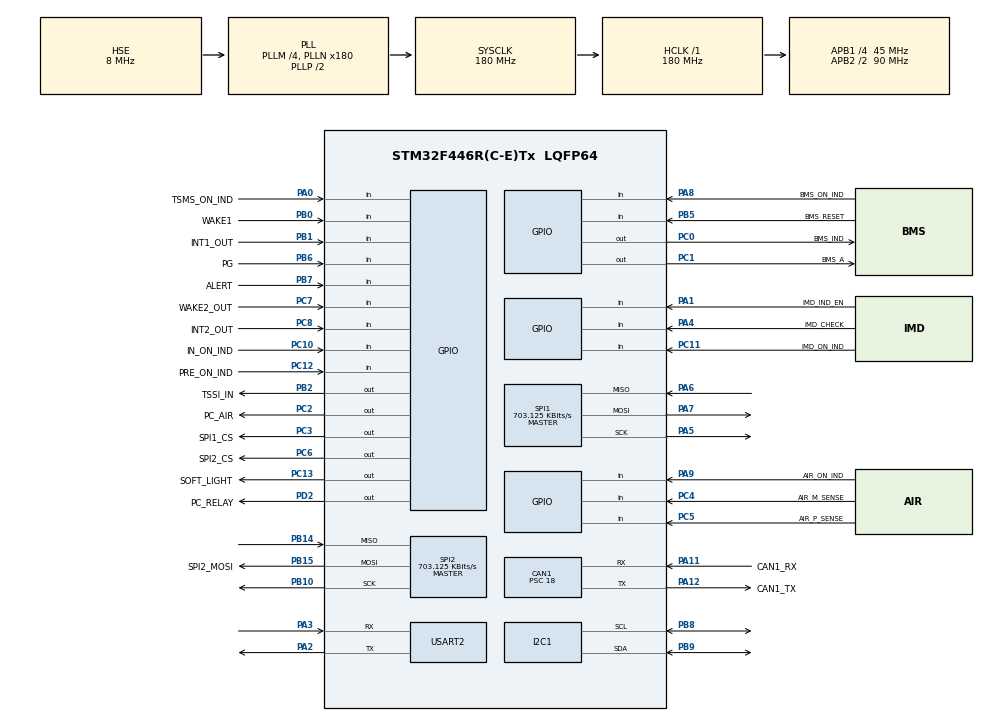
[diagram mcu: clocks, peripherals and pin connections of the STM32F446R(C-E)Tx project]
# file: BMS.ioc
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CAN1.BS1=CAN_BS1_3TQ
CAN1.CalculateBaudRate=500000
CAN1.CalculateTimeBit=2000
CAN1.CalculateTimeQuantum=400.0
CAN1.Prescaler=18
Dma.Request0=USART2_RX
Dma.Request1=USART2_TX
Dma.USART2_RX.0.Direction=DMA_PERIPH_TO_MEMORY
Dma.USART2_RX.0.FIFOMode=DMA_FIFOMODE_DISABLE
Dma.USART2_RX.0.Instance=DMA1_Stream5
Dma.USART2_RX.0.MemDataAlignment=DMA_MDATAALIGN_BYTE
Dma.USART2_RX.0.MemInc=DMA_MINC_ENABLE
Dma.USART2_RX.0.Mode=DMA_CIRCULAR
Dma.USART2_RX.0.PeriphDataAlignment=DMA_PDATAALIGN_BYTE
Dma.USART2_RX.0.PeriphInc=DMA_PINC_DISABLE
Dma.USART2_RX.0.Priority=DMA_PRIORITY_LOW
Dma.USART2_TX.1.Direction=DMA_MEMORY_TO_PERIPH
Dma.USART2_TX.1.FIFOMode=DMA_FIFOMODE_DISABLE
Dma.USART2_TX.1.Instance=DMA1_Stream6
Dma.USART2_TX.1.MemDataAlignment=DMA_MDATAALIGN_BYTE
Dma.USART2_TX.1.MemInc=DMA_MINC_ENABLE
Dma.USART2_TX.1.Mode=DMA_NORMAL
Dma.USART2_TX.1.PeriphDataAlignment=DMA_PDATAALIGN_BYTE
Dma.USART2_TX.1.PeriphInc=DMA_PINC_DISABLE
Dma.USART2_TX.1.Priority=DMA_PRIORITY_LOW
FREERTOS.CountingSemaphores01=canTxMailboxSem,3,Dynamic,NULL,3;uartTxSem,1,Dynamic,NULL,0
FREERTOS.Mutexes01=ADBMSMutex,Dynamic,NULL,Available;canTxMutex,Dynamic,NULL,Available;canRxMutex,Dynamic,NULL,Available;tpsDataMutex,Dynamic,NULL,Available;tpsI2cMutex,Dynamic,NULL,Available;logMutex,Dynamic,NULL,Available;uartTxMutex,Dynamic,NULL,Available
FREERTOS.Queues01=canTxQueue,16,FEB_CAN_Message_t,0,Dynamic,NULL,NULL;canRxQueue,32,FEB_CAN_Message_t,0,Dynamic,NULL,NULL;uartRxQueue,8,FEB_UART_RxQueueMsg_t,0,Dynamic,NULL,NULL
FREERTOS.Tasks01=uartRxTask,24,1024,StartUartRxTask,As weak,NULL,Dynamic,NULL,NULL;ADBMSTask,48,2048,StartADBMSTask,As weak,NULL,Dynamic,NULL,NULL;TPSTask,8,512,StartTPSTask,As weak,NULL,Dynamic,NULL,NULL;BMSTaskRx,8,1024,StartBMSTaskRx,As weak,NULL,Dynamic,NULL,NULL;BMSTaskTx,8,1024,StartBMSTaskTx,As weak,NULL,Dynamic,NULL,NULL;SMTask,24,1024,StartSMTask,As weak,NULL,Dynamic,NULL,NULL
FREERTOS.configCHECK_FOR_STACK_OVERFLOW=2
FREERTOS.configENABLE_FPU=1
FREERTOS.configTOTAL_HEAP_SIZE=65536
Mcu.Family=STM32F4
Mcu.Name=STM32F446R(C-E)Tx
Mcu.Package=LQFP64
NVIC.CAN1_RX0_IRQn=true\:5\:0\:false\:false\:true\:true\:true\:true\:true
NVIC.CAN1_RX1_IRQn=true\:5\:0\:false\:false\:true\:true\:true\:true\:true
NVIC.CAN1_SCE_IRQn=true\:5\:0\:false\:false\:true\:true\:true\:true\:true
NVIC.CAN1_TX_IRQn=true\:5\:0\:false\:false\:true\:true\:true\:true\:true
NVIC.DMA1_Stream5_IRQn=true\:5\:0\:false\:false\:true\:true\:false\:true\:true
NVIC.DMA1_Stream6_IRQn=true\:5\:0\:false\:false\:true\:true\:false\:true\:true
NVIC.PriorityGroup=NVIC_PRIORITYGROUP_4
NVIC.TIM6_DAC_IRQn=true\:15\:0\:false\:false\:true\:false\:false\:true\:true
NVIC.TimeBase=TIM6_DAC_IRQn
NVIC.TimeBaseIP=TIM6
NVIC.USART2_IRQn=true\:5\:0\:false\:false\:true\:true\:true\:true\:true
PA0-WKUP.GPIO_Label=TSMS_ON_IND
PA0-WKUP.Signal=GPIO_Input
PA1.GPIO_Label=IMD_IND_EN
PA1.Signal=GPIO_Input
PA11.GPIO_Label=CAN1_RX
PA11.Mode=CAN_Activate
PA11.Signal=CAN1_RX
PA12.GPIO_Label=CAN1_TX
PA12.Mode=CAN_Activate
PA12.Signal=CAN1_TX
PA13.Mode=Serial_Wire
PA13.Signal=SYS_JTMS-SWDIO
PA14.Mode=Serial_Wire
PA14.Signal=SYS_JTCK-SWCLK
PA2.Mode=Asynchronous
PA2.Signal=USART2_TX
PA3.Mode=Asynchronous
PA3.Signal=USART2_RX
PA4.GPIO_Label=IMD_CHECK
PA4.Signal=GPIO_Input
PA5.Mode=Full_Duplex_Master
PA5.Signal=SPI1_SCK
PA6.Mode=Full_Duplex_Master
PA6.Signal=SPI1_MISO
PA7.Mode=Full_Duplex_Master
PA7.Signal=SPI1_MOSI
PA8.GPIO_Label=BMS_ON_IND
PA8.Signal=GPIO_Input
PA9.GPIO_Label=AIR_ON_IND
PA9.Signal=GPIO_Input
PB0.GPIO_Label=WAKE1
PB0.Signal=GPIO_Input
PB1.GPIO_Label=INT1_OUT
PB1.Signal=GPIO_Input
PB10.Mode=Full_Duplex_Master
PB10.Signal=SPI2_SCK
PB14.Mode=Full_Duplex_Master
PB14.Signal=SPI2_MISO
PB15.GPIO_Label=SPI2_MOSI
PB15.Mode=Full_Duplex_Master
PB15.Signal=SPI2_MOSI
PB2.GPIO_Label=TSSI_IN
PB2.Signal=GPIO_Output
PB5.GPIO_Label=BMS_RESET
PB5.GPIO_PuPd=GPIO_PULLUP
PB5.Signal=GPIO_Input
PB6.GPIO_Label=PG
PB6.Signal=GPIO_Input
PB7.GPIO_Label=ALERT
PB7.Signal=GPIO_Input
PB8.Mode=I2C
PB8.Signal=I2C1_SCL
PB9.Mode=I2C
PB9.Signal=I2C1_SDA
PC0.GPIO_Label=BMS_IND
PC0.Signal=GPIO_Output
PC1.GPIO_Label=BMS_A
PC1.Signal=GPIO_Output
PC10.GPIO_Label=IN_ON_IND
PC10.Signal=GPIO_Input
PC11.GPIO_Label=IMD_ON_IND
PC11.Signal=GPIO_Input
PC12.GPIO_Label=PRE_ON_IND
PC12.Signal=GPIO_Input
PC13.GPIO_Label=SOFT_LIGHT
PC13.Signal=GPIO_Output
PC2.GPIO_Label=PC_AIR
PC2.Signal=GPIO_Output
PC3.GPIO_Label=SPI1_CS
PC3.Signal=GPIO_Output
PC4.GPIO_Label=AIR_M_SENSE
PC4.Signal=GPIO_Input
PC5.GPIO_Label=AIR_P_SENSE
PC5.Signal=GPIO_Input
PC6.GPIO_Label=SPI2_CS
PC6.Signal=GPIO_Output
PC7.GPIO_Label=WAKE2_OUT
PC7.Signal=GPIO_Input
PC8.GPIO_Label=INT2_OUT
PC8.Signal=GPIO_Input
PD2.GPIO_Label=PC_RELAY
PD2.Signal=GPIO_Output
PH0-OSC_IN.Mode=HSE-External-Oscillator
PH0-OSC_IN.Signal=RCC_OSC_IN
PH1-OSC_OUT.Mode=HSE-External-Oscillator
PH1-OSC_OUT.Signal=RCC_OSC_OUT
ProjectManager.HeapSize=0x200
ProjectManager.StackSize=0x400
ProjectManager.TargetToolchain=CMake
RCC.AHBFreq_Value=180000000
RCC.APB1CLKDivider=RCC_HCLK_DIV4
RCC.APB1Freq_Value=45000000
RCC.APB1TimFreq_Value=90000000
RCC.APB2CLKDivider=RCC_HCLK_DIV2
RCC.APB2Freq_Value=90000000
RCC.APB2TimFreq_Value=180000000
RCC.CortexFreq_Value=180000000
RCC.HCLKFreq_Value=180000000
RCC.HSE_VALUE=8000000
RCC.PLLM=4
RCC.PLLN=180
RCC.PLLSourceVirtual=RCC_PLLSOURCE_HSE
RCC.SYSCLKFreq_VALUE=180000000
RCC.SYSCLKSource=RCC_SYSCLKSOURCE_PLLCLK
RCC.USBFreq_Value=180000000
RCC.VCOOutputFreq_Value=360000000
SPI1.BaudRatePrescaler=SPI_BAUDRATEPRESCALER_128
SPI1.CLKPhase=SPI_PHASE_1EDGE
SPI1.CLKPolarity=SPI_POLARITY_LOW
SPI1.CalculateBaudRate=703.125 KBits/s
SPI1.Direction=SPI_DIRECTION_2LINES
SPI1.Mode=SPI_MODE_MASTER
SPI1.VirtualType=VM_MASTER
SPI2.BaudRatePrescaler=SPI_BAUDRATEPRESCALER_64
SPI2.CLKPhase=SPI_PHASE_1EDGE
SPI2.CLKPolarity=SPI_POLARITY_LOW
SPI2.CalculateBaudRate=703.125 KBits/s
SPI2.Direction=SPI_DIRECTION_2LINES
SPI2.Mode=SPI_MODE_MASTER
SPI2.VirtualType=VM_MASTER
USART2.VirtualMode=VM_ASYNC
VP_FREERTOS_VS_CMSIS_V2.Mode=CMSIS_V2
VP_SYS_VS_tim6.Mode=TIM6
board=custom

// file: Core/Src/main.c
/* USER CODE BEGIN Header */
/**
  ******************************************************************************
  * @file           : main.c
  * @brief          : Main program body
  ******************************************************************************
  * @attention
  *
  * Copyright (c) 2025 STMicroelectronics.
  * All rights reserved.
  *
  * This software is licensed under terms that can be found in the LICENSE file
  * in the root directory of this software component.
  * If no LICENSE file comes with this software, it is provided AS-IS.
  *
  ******************************************************************************
  */
/* USER CODE END Header */
#include "main.h"
#include "cmsis_os.h"
#include "can.h"
#include "dma.h"
#include "i2c.h"
#include "spi.h"
#include "usart.h"
#include "gpio.h"

/* USER CODE BEGIN Includes */
#include "FEB_ADBMS6830B.h"
#include "FEB_CAN_State.h"
#include "FEB_CAN_PingPong.h"
#include "FEB_HW.h"
#include "FEB_Main.h"
#include "FEB_SM.h"
#include "task.h"
/* USER CODE END Includes */

/* USER CODE BEGIN PV */
extern osThreadId_t SMTaskHandle;
/* USER CODE END PV */

void SystemClock_Config(void);
void MX_FREERTOS_Init(void);

int main(void)
{

  /* MCU Configuration--------------------------------------------------------*/

  /* Reset of all peripherals, Initializes the Flash interface and the Systick. */
  HAL_Init();

  /* Configure the system clock */
  SystemClock_Config();

  /* Initialize all configured peripherals */
  MX_GPIO_Init();
  MX_DMA_Init();
  MX_USART2_UART_Init();
  MX_SPI1_Init();
  MX_I2C1_Init();
  MX_CAN1_Init();
  MX_SPI2_Init();
  /* USER CODE BEGIN 2 */
  printf("[BOOT] UART ready @115200 (USART2)\r\n");
  /* USER CODE END 2 */

  /* Init scheduler */
  osKernelInitialize();  /* Call init function for freertos objects (in cmsis_os2.c) */
  MX_FREERTOS_Init();

  /* Start scheduler */
  osKernelStart();

  /* We should never get here as control is now taken by the scheduler */

  /* Infinite loop */
  while (1)
  {

  }
}

void SystemClock_Config(void)
{
  RCC_OscInitTypeDef RCC_OscInitStruct = {0};
  RCC_ClkInitTypeDef RCC_ClkInitStruct = {0};

  /** Configure the main internal regulator output voltage
  */
  __HAL_RCC_PWR_CLK_ENABLE();
  __HAL_PWR_VOLTAGESCALING_CONFIG(PWR_REGULATOR_VOLTAGE_SCALE1);

  /** Initializes the RCC Oscillators according to the specified parameters
  * in the RCC_OscInitTypeDef structure.
  */
  RCC_OscInitStruct.OscillatorType = RCC_OSCILLATORTYPE_HSE;
  RCC_OscInitStruct.HSEState = RCC_HSE_ON;
  RCC_OscInitStruct.PLL.PLLState = RCC_PLL_ON;
  RCC_OscInitStruct.PLL.PLLSource = RCC_PLLSOURCE_HSE;
  RCC_OscInitStruct.PLL.PLLM = 4;
  RCC_OscInitStruct.PLL.PLLN = 180;
  RCC_OscInitStruct.PLL.PLLP = RCC_PLLP_DIV2;
  RCC_OscInitStruct.PLL.PLLQ = 2;
  RCC_OscInitStruct.PLL.PLLR = 2;
  if (HAL_RCC_OscConfig(&RCC_OscInitStruct) != HAL_OK)
  {
    Error_Handler();
  }

  /** Activate the Over-Drive mode
  */
  if (HAL_PWREx_EnableOverDrive() != HAL_OK)
  {
    Error_Handler();
  }

  /** Initializes the CPU, AHB and APB buses clocks
  */
  RCC_ClkInitStruct.ClockType = RCC_CLOCKTYPE_HCLK|RCC_CLOCKTYPE_SYSCLK
                              |RCC_CLOCKTYPE_PCLK1|RCC_CLOCKTYPE_PCLK2;
  RCC_ClkInitStruct.SYSCLKSource = RCC_SYSCLKSOURCE_PLLCLK;
  RCC_ClkInitStruct.AHBCLKDivider = RCC_SYSCLK_DIV1;
  RCC_ClkInitStruct.APB1CLKDivider = RCC_HCLK_DIV4;
  RCC_ClkInitStruct.APB2CLKDivider = RCC_HCLK_DIV2;

  if (HAL_RCC_ClockConfig(&RCC_ClkInitStruct, FLASH_LATENCY_5) != HAL_OK)
  {
    Error_Handler();
  }
}

void HAL_TIM_PeriodElapsedCallback(TIM_HandleTypeDef *htim)
{
  if (htim->Instance == TIM6)
  {
    HAL_IncTick();
  }
  /* USER CODE BEGIN Callback 1 */
  /* All processing happens in SMTask (safe task context) */
  if (SMTaskHandle != NULL)
  {
    BaseType_t xHigherPriorityTaskWoken = pdFALSE;
    vTaskNotifyGiveFromISR((TaskHandle_t)SMTaskHandle, &xHigherPriorityTaskWoken);
    portYIELD_FROM_ISR(xHigherPriorityTaskWoken);
  }
  /* NOTE: FEB_SM_Process(), FEB_CAN_State_Tick(), FEB_CAN_PingPong_Tick()
     are called from SMTask, not from ISR - they use blocking operations */
  /* USER CODE END Callback 1 */
}

void Error_Handler(void)
{
  __disable_irq();
  while (1)
  {
  }
}
